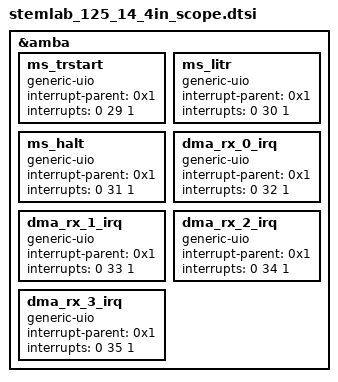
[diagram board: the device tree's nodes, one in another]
/dts-v1/;
/plugin/;
/include/ "../tmp/stemlab_125_14_4in_scope.tree/pl.dtsi"
/ {
    fragment@3 {
        target = <&amba>;
        overlay3: __overlay__ {
            ms_trstart: ms_trstart {
                compatible = "generic-uio";
                interrupt-parent = <0x1>;
                interrupts = <0 29 1>;
            };
            ms_litr: ms_litr {
                compatible = "generic-uio";
                interrupt-parent = <0x1>;
                interrupts = <0 30 1>;
            };
            ms_halt: ms_halt {
                compatible = "generic-uio";
                interrupt-parent = <0x1>;
                interrupts = <0 31 1>;
            };
            dma_rx_0_irq: dma_rx_0_irq {
                compatible = "generic-uio";
                interrupt-parent = <0x1>;
                interrupts = <0 32 1>;
            };
            dma_rx_1_irq: dma_rx_1_irq {
                compatible = "generic-uio";
                interrupt-parent = <0x1>;
                interrupts = <0 33 1>;
            };
            dma_rx_2_irq: dma_rx_2_irq {
                compatible = "generic-uio";
                interrupt-parent = <0x1>;
                interrupts = <0 34 1>;
            };
            dma_rx_3_irq: dma_rx_3_irq {
                compatible = "generic-uio";
                interrupt-parent = <0x1>;
                interrupts = <0 35 1>;
            };
        };
    };
};
